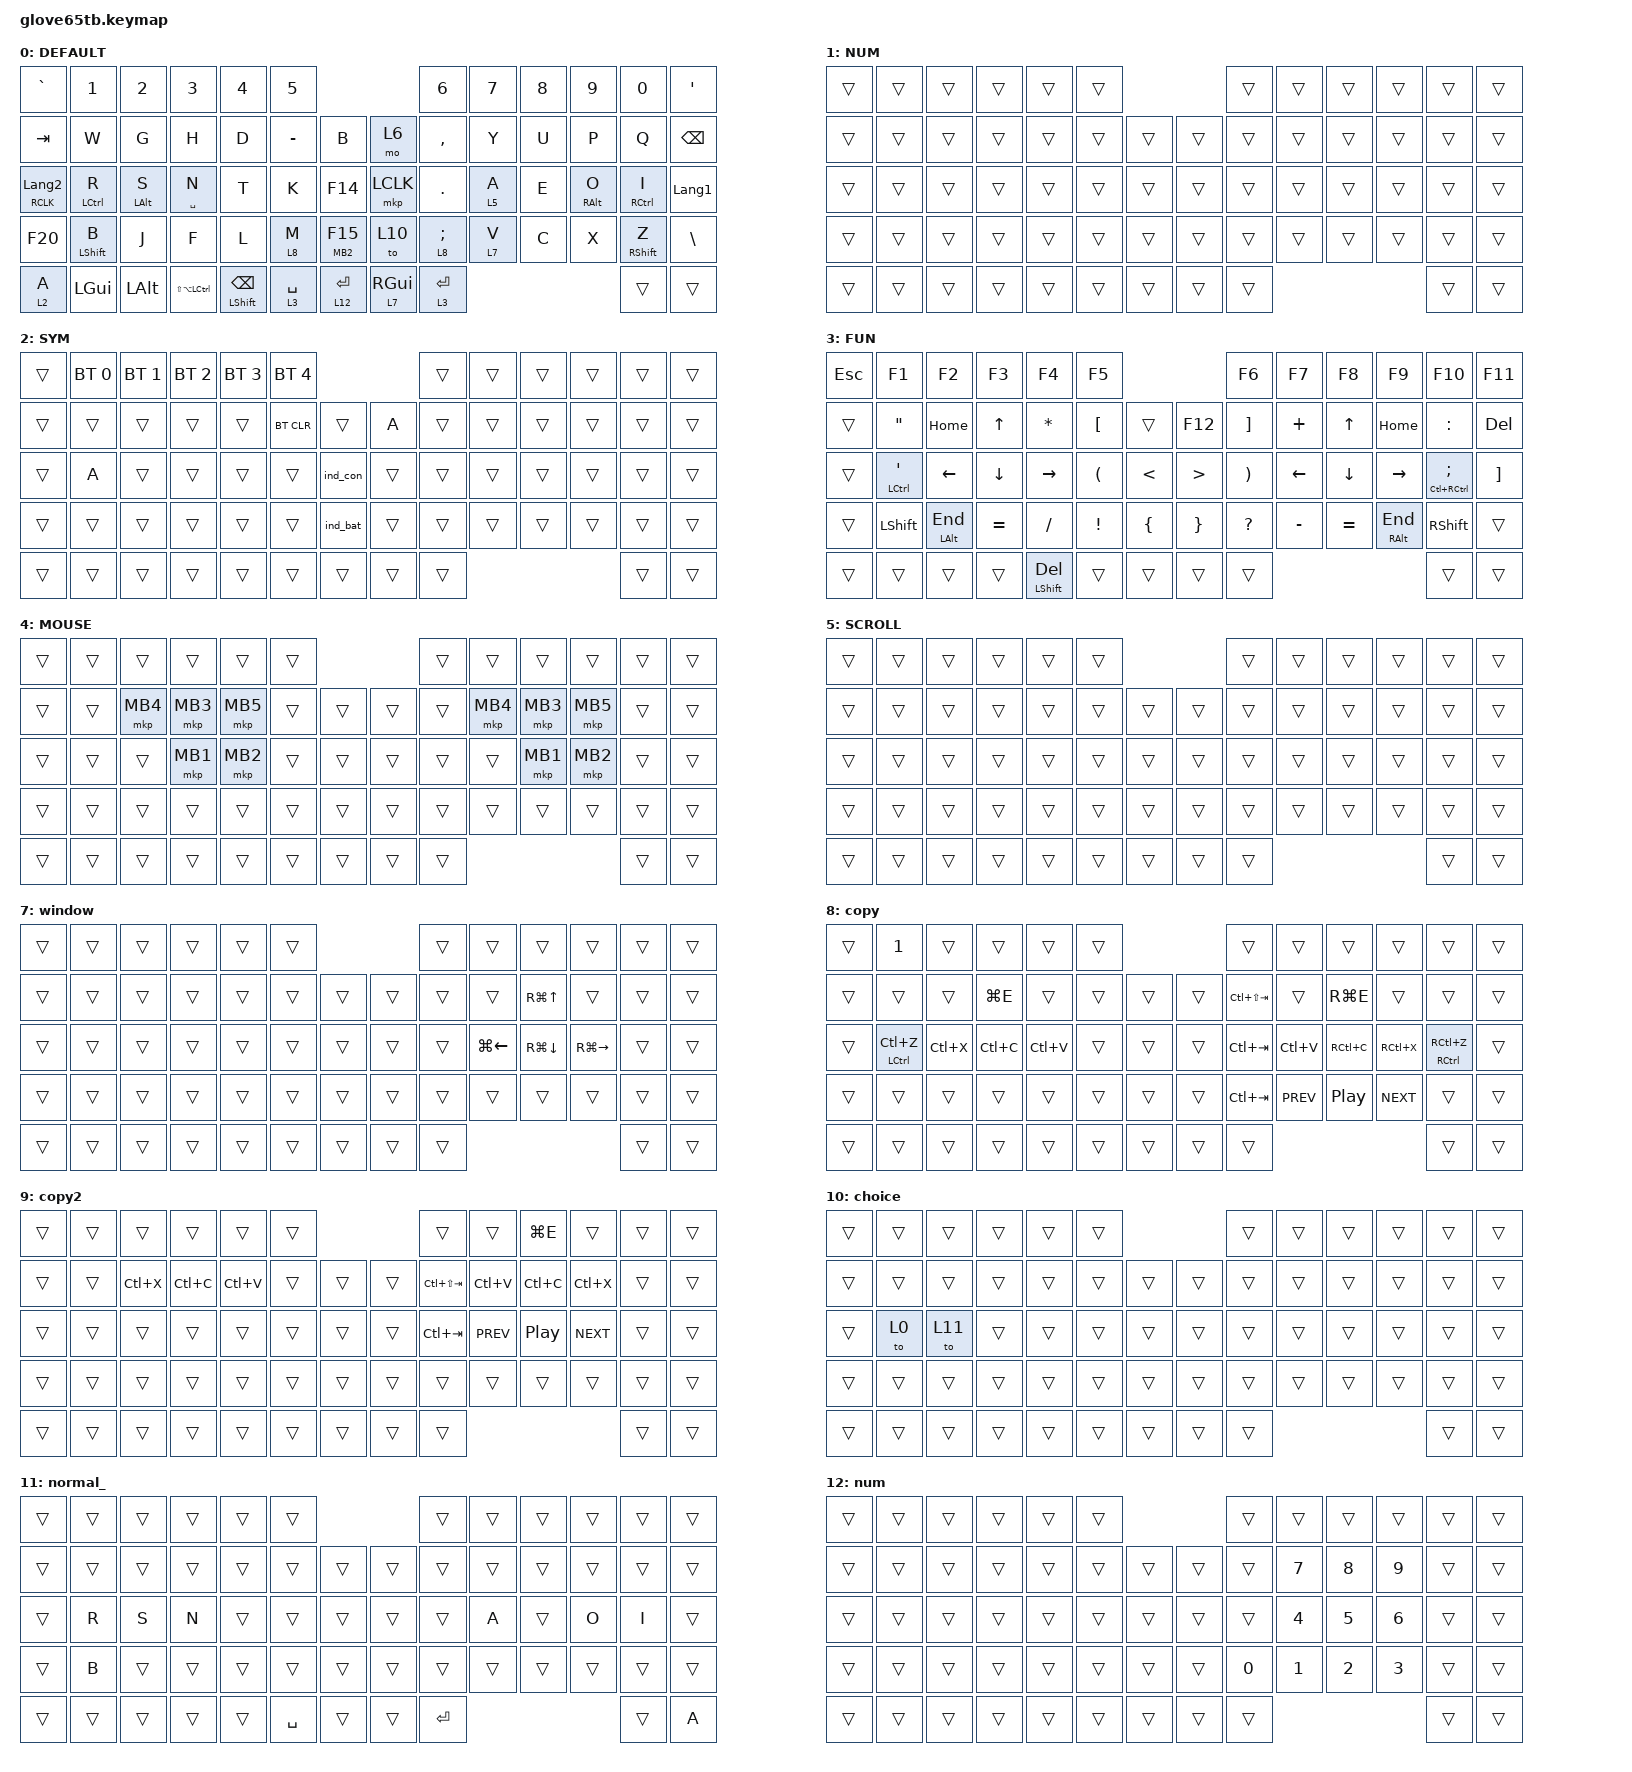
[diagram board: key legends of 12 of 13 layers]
#define ZMK_POINTING_DEFAULT_SCRL_VAL 150

#include <behaviors/rgbled_widget.dtsi>
#include <dt-bindings/zmk/input_transform.h>
#include <input/processors.dtsi>
#include <zephyr/dt-bindings/input/input-event-codes.h>
#include <behaviors.dtsi>
#include <dt-bindings/zmk/bt.h>
#include <dt-bindings/zmk/keys.h>
#include <dt-bindings/zmk/pointing.h>

// Layer Numbering

#define DEFAULT 0
#define NUM     1
#define SYM     2
#define FUN     3
#define MOUSE   4
#define SCROLL  5

&mmv {
    delay-ms = <20>;
    trigger-period-ms = <5>;
    time-to-max-speed-ms = <100>;
    acceleration-exponent = <2>;
};

&msc {
    delay-ms = <12>;
    trigger-period-ms = <24>;
    time-to-max-speed-ms = <0>;
    acceleration-exponent = <0>;
};

/*
//クリック後0.25秒でaml解除
&mkp_input_listener { input-processors = <&zip_temp_layer 5 250>; };
*/

/ {
    input_processors {
        zip_wheel_scaler: zip_wheel_scaler {
            compatible = "zmk,input-processor-scaler";
            #input-processor-cells = <2>;
            type = <INPUT_EV_REL>;
            codes = <INPUT_REL_WHEEL>;
            track-remainders;
        };
    };
};

/*
&msc_input_listener {
  input-processors = <&zip_wheel_scaler 1 4>;
};
*/

/ {
    combos {
        compatible = "zmk,combos";

        scroll {
            bindings = <&mo 5>;
            key-positions = <49 50>;
        };

        test {
            bindings = <&none>;
            key-positions = <58 52 36 37 22 27 38>;
        };
    };

    behaviors {
        sensor_rotate_kp: sensor_rotate_kp {
            compatible = "zmk,behavior-sensor-rotate-var";
            #sensor-binding-cells = <2>;
            bindings = <&kp>, <&kp>;

            tap-ms = <20>;
        };

        mouse_wheel_scroll: mouse_wheel_scroll {
            compatible = "zmk,behavior-sensor-rotate-var";
            #sensor-binding-cells = <2>;
            bindings = <&msc>, <&msc>;

            tap-ms = <16>;
        };

        hold_tap_kp_kp: hold_tap_kp_kp {
            compatible = "zmk,behavior-hold-tap";
            label = "HOLD_TAP_KP_KP";
            bindings = <&kp>, <&kp>;

            #binding-cells = <2>;
            tapping-term-ms = <100>;
        };

        hold_tap_mo_kp: hold_tap_mo_kp {
            compatible = "zmk,behavior-hold-tap";
            label = "HOLD_TAP_MO_KP";
            bindings = <&mo>, <&kp>;

            #binding-cells = <2>;
            tapping-term-ms = <100>;
        };

        hold_tap_kp_kp_90: hold_tap_kp_kp_90 {
            compatible = "zmk,behavior-hold-tap";
            label = "HOLD_TAP_KP_KP_90";
            bindings = <&kp>, <&kp>;

            #binding-cells = <2>;
            tapping-term-ms = <90>;
        };

        hold_tap_kp_kp_120: hold_tap_kp_kp_120 {
            compatible = "zmk,behavior-hold-tap";
            label = "HOLD_TAP_KP_KP_120";
            bindings = <&kp>, <&kp>;

            #binding-cells = <2>;
            tapping-term-ms = <120>;
        };

        hold_tap_mkp_kp: hold_tap_mkp_kp {
            compatible = "zmk,behavior-hold-tap";
            label = "HOLD_TAP_MKP_KP";
            bindings = <&mkp>, <&kp>;

            #binding-cells = <2>;
            tapping-term-ms = <100>;
        };
    };

    keymap {
        compatible = "zmk,keymap";

        default_layer {
            label = "DEFAULT";
            bindings = <
&kp GRAVE                         &kp N1                          &kp N2                  &kp N3                      &kp N4                                   &kp N5                                                                          &kp N6                       &kp N7               &kp N8  &kp N9                           &kp N0                             &kp SINGLE_QUOTE
&kp TAB                           &kp W                           &kp G                   &kp H                       &kp D                                    &kp MINUS                &kp B                     &mo 6                        &kp COMMA                    &kp Y                &kp U   &kp P                            &kp Q                              &kp BACKSPACE
&hold_tap_mkp_kp RCLK LANGUAGE_2  &hold_tap_kp_kp LEFT_CONTROL R  &hold_tap_kp_kp LALT S  &hold_tap_kp_kp_90 SPACE N  &kp T                                    &kp K                    &kp F14                   &mkp LCLK                    &kp PERIOD                   &hold_tap_mo_kp 5 A  &kp E   &hold_tap_kp_kp_120 RIGHT_ALT O  &hold_tap_kp_kp_120 RCTRL I        &kp LANGUAGE_1
&kp F20                           &hold_tap_kp_kp LEFT_SHIFT B    &kp J                   &kp F                       &kp L                                    &hold_tap_mo_kp 8 M      &hold_tap_mkp_kp MB2 F15  &to 10                       &hold_tap_mo_kp 8 SEMICOLON  &hold_tap_mo_kp 7 V  &kp C   &kp X                            &hold_tap_kp_kp_120 RIGHT_SHIFT Z  &kp BACKSLASH
&hold_tap_mo_kp 2 A               &kp LEFT_GUI                    &kp LEFT_ALT            &kp LS(LA(LCTRL))           &hold_tap_kp_kp_90 LEFT_SHIFT BACKSPACE  &hold_tap_mo_kp 3 SPACE  &hold_tap_mo_kp 12 ENTER  &hold_tap_mo_kp 7 RIGHT_GUI  &hold_tap_mo_kp 3 ENTER                                                                    &trans                             &trans
            >;

            sensor-bindings = <&sensor_rotate_kp F16 F17>;
        };

        number_layer {
            label = "NUM";
            bindings = <
&trans  &trans  &trans  &trans  &trans  &trans                  &trans  &trans  &trans  &trans  &trans  &trans
&trans  &trans  &trans  &trans  &trans  &trans  &trans  &trans  &trans  &trans  &trans  &trans  &trans  &trans
&trans  &trans  &trans  &trans  &trans  &trans  &trans  &trans  &trans  &trans  &trans  &trans  &trans  &trans
&trans  &trans  &trans  &trans  &trans  &trans  &trans  &trans  &trans  &trans  &trans  &trans  &trans  &trans
&trans  &trans  &trans  &trans  &trans  &trans  &trans  &trans  &trans                          &trans  &trans
            >;
        };

        symbol_layer {
            label = "SYM";
            bindings = <
&trans  &bt BT_SEL 0  &bt BT_SEL 1  &bt BT_SEL 2  &bt BT_SEL 3  &bt BT_SEL 4                    &trans  &trans  &trans  &trans  &trans  &trans
&trans  &trans        &trans        &trans        &trans        &bt BT_CLR    &trans    &kp A   &trans  &trans  &trans  &trans  &trans  &trans
&trans  &kp A         &trans        &trans        &trans        &trans        &ind_con  &trans  &trans  &trans  &trans  &trans  &trans  &trans
&trans  &trans        &trans        &trans        &trans        &trans        &ind_bat  &trans  &trans  &trans  &trans  &trans  &trans  &trans
&trans  &trans        &trans        &trans        &trans        &trans        &trans    &trans  &trans                          &trans  &trans
            >;
        };

        FN {
            label = "FUN";
            bindings = <
&kp ESC  &kp F1                     &kp F2                        &kp F3          &kp F4                         &kp F5                                                  &kp F6                 &kp F7          &kp F8          &kp F9                         &kp F10                              &kp F11
&trans   &kp DOUBLE_QUOTES          &kp HOME                      &kp UP_ARROW    &kp ASTERISK                   &kp LEFT_BRACKET      &trans          &kp F12           &kp RIGHT_BRACKET      &kp PLUS        &kp UP_ARROW    &kp HOME                       &kp COLON                            &kp DELETE
&trans   &hold_tap_kp_kp LCTRL SQT  &kp LEFT_ARROW                &kp DOWN_ARROW  &kp RIGHT_ARROW                &kp LEFT_PARENTHESIS  &kp LESS_THAN   &kp GREATER_THAN  &kp RIGHT_PARENTHESIS  &kp LEFT_ARROW  &kp DOWN_ARROW  &kp RIGHT_ARROW                &hold_tap_kp_kp LC(RCTRL) SEMICOLON  &kp RIGHT_BRACKET
&trans   &kp LEFT_SHIFT             &hold_tap_kp_kp LEFT_ALT END  &kp EQUAL       &kp SLASH                      &kp EXCLAMATION       &kp LEFT_BRACE  &kp RIGHT_BRACE   &kp QUESTION           &kp MINUS       &kp EQUAL       &hold_tap_kp_kp RIGHT_ALT END  &kp RIGHT_SHIFT                      &trans
&trans   &trans                     &trans                        &trans          &hold_tap_kp_kp LSHIFT DELETE  &trans                &trans          &trans            &trans                                                                                &trans                               &trans
            >;

            sensor-bindings = <&sensor_rotate_kp F18 F19>;
        };

        mouse_layer {
            label = "MOUSE";
            bindings = <
&trans  &trans  &trans    &trans    &trans    &trans                  &trans  &trans    &trans    &trans    &trans  &trans
&trans  &trans  &mkp MB4  &mkp MB3  &mkp MB5  &trans  &trans  &trans  &trans  &mkp MB4  &mkp MB3  &mkp MB5  &trans  &trans
&trans  &trans  &trans    &mkp MB1  &mkp MB2  &trans  &trans  &trans  &trans  &trans    &mkp MB1  &mkp MB2  &trans  &trans
&trans  &trans  &trans    &trans    &trans    &trans  &trans  &trans  &trans  &trans    &trans    &trans    &trans  &trans
&trans  &trans  &trans    &trans    &trans    &trans  &trans  &trans  &trans                                &trans  &trans
            >;
        };

        scroll_layer {
            label = "SCROLL";
            bindings = <
&trans  &trans  &trans  &trans  &trans  &trans                  &trans  &trans  &trans  &trans  &trans  &trans
&trans  &trans  &trans  &trans  &trans  &trans  &trans  &trans  &trans  &trans  &trans  &trans  &trans  &trans
&trans  &trans  &trans  &trans  &trans  &trans  &trans  &trans  &trans  &trans  &trans  &trans  &trans  &trans
&trans  &trans  &trans  &trans  &trans  &trans  &trans  &trans  &trans  &trans  &trans  &trans  &trans  &trans
&trans  &trans  &trans  &trans  &trans  &trans  &trans  &trans  &trans                          &trans  &trans
            >;
        };

        Macro {
            bindings = <
&trans  &trans  &kp LA(F24)  &trans  &trans  &trans                               &trans  &trans  &trans  &trans  &trans  &trans
&trans  &trans  &trans       &trans  &trans  &trans  &trans  &trans               &trans  &trans  &trans  &trans  &trans  &trans
&trans  &trans  &trans       &trans  &trans  &trans  &trans  &trans               &trans  &trans  &trans  &trans  &trans  &trans
&trans  &trans  &trans       &trans  &trans  &trans  &trans  &kp LS(LA(LC(F24)))  &trans  &trans  &trans  &trans  &trans  &trans
&trans  &trans  &trans       &trans  &trans  &trans  &trans  &trans               &trans                          &trans  &trans
            >;
        };

        window {
            bindings = <
&trans  &trans  &trans  &trans  &trans  &trans                  &trans  &trans              &trans              &trans               &trans  &trans
&trans  &trans  &trans  &trans  &trans  &trans  &trans  &trans  &trans  &trans              &kp RG(UP_ARROW)    &trans               &trans  &trans
&trans  &trans  &trans  &trans  &trans  &trans  &trans  &trans  &trans  &kp LG(LEFT_ARROW)  &kp RG(DOWN_ARROW)  &kp RG(RIGHT_ARROW)  &trans  &trans
&trans  &trans  &trans  &trans  &trans  &trans  &trans  &trans  &trans  &trans              &trans              &trans               &trans  &trans
&trans  &trans  &trans  &trans  &trans  &trans  &trans  &trans  &trans                                                               &trans  &trans
            >;
        };

        copy {
            bindings = <
&trans  &kp NUMBER_1                 &trans     &trans     &trans     &trans                  &trans           &trans      &trans            &trans      &trans                       &trans
&trans  &trans                       &trans     &kp LG(E)  &trans     &trans  &trans  &trans  &kp LC(LS(TAB))  &trans      &kp RG(E)         &trans      &trans                       &trans
&trans  &hold_tap_kp_kp LCTRL LC(Z)  &kp LC(X)  &kp LC(C)  &kp LC(V)  &trans  &trans  &trans  &kp LC(TAB)      &kp LC(V)   &kp RC(C)         &kp RC(X)   &hold_tap_kp_kp RCTRL RC(Z)  &trans
&trans  &trans                       &trans     &trans     &trans     &trans  &trans  &trans  &kp LC(TAB)      &kp C_PREV  &kp C_PLAY_PAUSE  &kp C_NEXT  &trans                       &trans
&trans  &trans                       &trans     &trans     &trans     &trans  &trans  &trans  &trans                                                     &trans                       &trans
            >;
        };

        copy2 {
            bindings = <
&trans  &trans  &trans     &trans     &trans     &trans                  &trans           &trans      &kp LG(E)         &trans      &trans  &trans
&trans  &trans  &kp LC(X)  &kp LC(C)  &kp LC(V)  &trans  &trans  &trans  &kp LC(LS(TAB))  &kp LC(V)   &kp LC(C)         &kp LC(X)   &trans  &trans
&trans  &trans  &trans     &trans     &trans     &trans  &trans  &trans  &kp LC(TAB)      &kp C_PREV  &kp C_PLAY_PAUSE  &kp C_NEXT  &trans  &trans
&trans  &trans  &trans     &trans     &trans     &trans  &trans  &trans  &trans           &trans      &trans            &trans      &trans  &trans
&trans  &trans  &trans     &trans     &trans     &trans  &trans  &trans  &trans                                                     &trans  &trans
            >;
        };

        choice {
            bindings = <
&trans  &trans  &trans  &trans  &trans  &trans                  &trans  &trans  &trans  &trans  &trans  &trans
&trans  &trans  &trans  &trans  &trans  &trans  &trans  &trans  &trans  &trans  &trans  &trans  &trans  &trans
&trans  &to 0   &to 11  &trans  &trans  &trans  &trans  &trans  &trans  &trans  &trans  &trans  &trans  &trans
&trans  &trans  &trans  &trans  &trans  &trans  &trans  &trans  &trans  &trans  &trans  &trans  &trans  &trans
&trans  &trans  &trans  &trans  &trans  &trans  &trans  &trans  &trans                          &trans  &trans
            >;
        };

        normal_ {
            bindings = <
&trans  &trans  &trans  &trans  &trans  &trans                     &trans     &trans  &trans  &trans  &trans  &trans
&trans  &trans  &trans  &trans  &trans  &trans     &trans  &trans  &trans     &trans  &trans  &trans  &trans  &trans
&trans  &kp R   &kp S   &kp N   &trans  &trans     &trans  &trans  &trans     &kp A   &trans  &kp O   &kp I   &trans
&trans  &kp B   &trans  &trans  &trans  &trans     &trans  &trans  &trans     &trans  &trans  &trans  &trans  &trans
&trans  &trans  &trans  &trans  &trans  &kp SPACE  &trans  &trans  &kp ENTER                          &trans  &kp A
            >;
        };

        num {
            bindings = <
&trans  &trans  &trans  &trans  &trans  &trans                  &trans        &trans        &trans        &trans        &trans  &trans
&trans  &trans  &trans  &trans  &trans  &trans  &trans  &trans  &trans        &kp NUMBER_7  &kp NUMBER_8  &kp NUMBER_9  &trans  &trans
&trans  &trans  &trans  &trans  &trans  &trans  &trans  &trans  &trans        &kp NUMBER_4  &kp NUMBER_5  &kp NUMBER_6  &trans  &trans
&trans  &trans  &trans  &trans  &trans  &trans  &trans  &trans  &kp NUMBER_0  &kp NUMBER_1  &kp NUMBER_2  &kp NUMBER_3  &trans  &trans
&trans  &trans  &trans  &trans  &trans  &trans  &trans  &trans  &trans                                                  &trans  &trans
            >;
        };
    };
};
